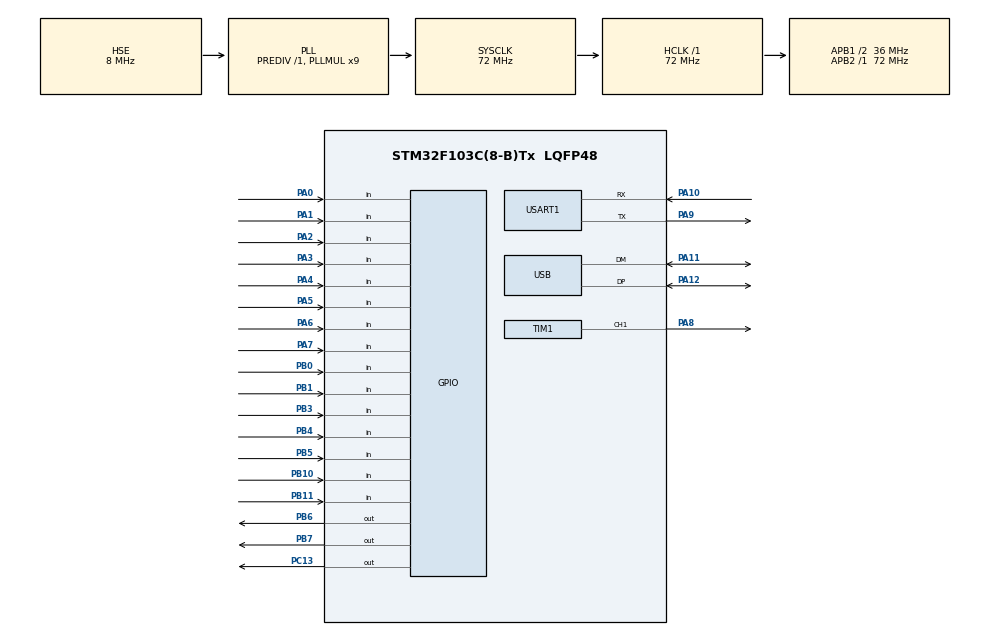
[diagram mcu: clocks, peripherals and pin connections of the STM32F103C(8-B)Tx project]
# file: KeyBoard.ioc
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Dma.Request0=TIM1_CH1
Dma.TIM1_CH1.0.Direction=DMA_MEMORY_TO_PERIPH
Dma.TIM1_CH1.0.Instance=DMA1_Channel2
Dma.TIM1_CH1.0.MemDataAlignment=DMA_MDATAALIGN_WORD
Dma.TIM1_CH1.0.MemInc=DMA_MINC_ENABLE
Dma.TIM1_CH1.0.Mode=DMA_NORMAL
Dma.TIM1_CH1.0.PeriphDataAlignment=DMA_PDATAALIGN_WORD
Dma.TIM1_CH1.0.PeriphInc=DMA_PINC_DISABLE
Dma.TIM1_CH1.0.Priority=DMA_PRIORITY_LOW
Mcu.Family=STM32F1
Mcu.Name=STM32F103C(8-B)Tx
Mcu.Package=LQFP48
NVIC.DMA1_Channel2_IRQn=true\:0\:0\:false\:false\:true\:false\:true\:true
NVIC.PriorityGroup=NVIC_PRIORITYGROUP_4
NVIC.USART1_IRQn=true\:0\:0\:false\:false\:true\:true\:true\:true
NVIC.USB_LP_CAN1_RX0_IRQn=true\:0\:0\:false\:false\:true\:false\:true\:true
PA0-WKUP.GPIO_PuPd=GPIO_PULLUP
PA0-WKUP.Signal=GPIO_Input
PA1.GPIO_PuPd=GPIO_PULLUP
PA1.Signal=GPIO_Input
PA10.Mode=Asynchronous
PA10.Signal=USART1_RX
PA11.Mode=Device
PA11.Signal=USB_DM
PA12.Mode=Device
PA12.Signal=USB_DP
PA13.Mode=Serial_Wire
PA13.Signal=SYS_JTMS-SWDIO
PA14.Mode=Serial_Wire
PA14.Signal=SYS_JTCK-SWCLK
PA2.GPIO_PuPd=GPIO_PULLUP
PA2.Signal=GPIO_Input
PA3.GPIO_PuPd=GPIO_PULLUP
PA3.Signal=GPIO_Input
PA4.GPIO_PuPd=GPIO_PULLUP
PA4.Signal=GPIO_Input
PA5.GPIO_PuPd=GPIO_PULLUP
PA5.Signal=GPIO_Input
PA6.GPIO_PuPd=GPIO_PULLUP
PA6.Signal=GPIO_Input
PA7.GPIO_PuPd=GPIO_PULLUP
PA7.Signal=GPIO_Input
PA8.Signal=S_TIM1_CH1
PA9.Mode=Asynchronous
PA9.Signal=USART1_TX
PB0.GPIO_PuPd=GPIO_PULLUP
PB0.Signal=GPIO_Input
PB1.GPIO_PuPd=GPIO_PULLUP
PB1.Signal=GPIO_Input
PB10.GPIO_PuPd=GPIO_PULLUP
PB10.Signal=GPIO_Input
PB11.GPIO_PuPd=GPIO_PULLUP
PB11.Signal=GPIO_Input
PB3.GPIO_PuPd=GPIO_PULLUP
PB3.Signal=GPIO_Input
PB4.GPIO_PuPd=GPIO_PULLUP
PB4.Signal=GPIO_Input
PB5.GPIO_PuPd=GPIO_PULLUP
PB5.Signal=GPIO_Input
PB6.GPIO_ModeDefaultOutputPP=GPIO_MODE_OUTPUT_OD
PB6.GPIO_PuPd=GPIO_PULLUP
PB6.GPIO_Speed=GPIO_SPEED_FREQ_HIGH
PB6.PinState=GPIO_PIN_SET
PB6.Signal=GPIO_Output
PB7.GPIO_ModeDefaultOutputPP=GPIO_MODE_OUTPUT_OD
PB7.GPIO_PuPd=GPIO_PULLUP
PB7.GPIO_Speed=GPIO_SPEED_FREQ_HIGH
PB7.PinState=GPIO_PIN_SET
PB7.Signal=GPIO_Output
PC13-TAMPER-RTC.GPIO_ModeDefaultOutputPP=GPIO_MODE_OUTPUT_PP
PC13-TAMPER-RTC.GPIO_PuPd=GPIO_PULLUP
PC13-TAMPER-RTC.GPIO_Speed=GPIO_SPEED_FREQ_HIGH
PC13-TAMPER-RTC.PinState=GPIO_PIN_SET
PC13-TAMPER-RTC.Signal=GPIO_Output
PC14-OSC32_IN.Mode=LSE-External-Oscillator
PC14-OSC32_IN.Signal=RCC_OSC32_IN
PC15-OSC32_OUT.Mode=LSE-External-Oscillator
PC15-OSC32_OUT.Signal=RCC_OSC32_OUT
PD0-OSC_IN.Mode=HSE-External-Oscillator
PD0-OSC_IN.Signal=RCC_OSC_IN
PD1-OSC_OUT.Mode=HSE-External-Oscillator
PD1-OSC_OUT.Signal=RCC_OSC_OUT
ProjectManager.HeapSize=0x200
ProjectManager.StackSize=0x400
ProjectManager.TargetToolchain=MDK-ARM V5.32
RCC.AHBFreq_Value=72000000
RCC.APB1CLKDivider=RCC_HCLK_DIV2
RCC.APB1Freq_Value=36000000
RCC.APB1TimFreq_Value=72000000
RCC.APB2Freq_Value=72000000
RCC.APB2TimFreq_Value=72000000
RCC.HCLKFreq_Value=72000000
RCC.PLLMUL=RCC_PLL_MUL9
RCC.SYSCLKFreq_VALUE=72000000
RCC.SYSCLKSource=RCC_SYSCLKSOURCE_PLLCLK
RCC.USBFreq_Value=48000000
RCC.USBPrescaler=RCC_USBCLKSOURCE_PLL_DIV1_5
SH.S_TIM1_CH1.0=TIM1_CH1,PWM Generation1 CH1
TIM1.Channel-PWM\ Generation1\ CH1=TIM_CHANNEL_1
TIM1.Period=89
TIM3.AutoReloadPreload=TIM_AUTORELOAD_PRELOAD_ENABLE
TIM3.Prescaler=3
USART1.VirtualMode=VM_ASYNC
USB_DEVICE.CLASS_NAME_FS=HID
USB_DEVICE.MANUFACTURER_STRING=KeyBoard
USB_DEVICE.PID_HID_FS=11451
USB_DEVICE.PRODUCT_STRING_HID_FS=KeyBoard
USB_DEVICE.VID=1145
USB_DEVICE.VirtualMode=Hid
USB_DEVICE.VirtualModeFS=Hid_FS
VP_RTC_VS_RTC_Activate.Mode=RTC_Enabled
VP_TIM1_VS_ClockSourceINT.Mode=Internal
VP_TIM3_VS_ClockSourceINT.Mode=Internal
VP_USB_DEVICE_VS_USB_DEVICE_HID_FS.Mode=HID_FS
board=custom

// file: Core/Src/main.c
/* USER CODE BEGIN Header */
/**
  ******************************************************************************
  * @file           : main.c
  * @brief          : Main program body
  ******************************************************************************
  * @attention
  *
  * Copyright (c) 2024 STMicroelectronics.
  * All rights reserved.
  *
  * This software is licensed under terms that can be found in the LICENSE file
  * in the root directory of this software component.
  * If no LICENSE file comes with this software, it is provided AS-IS.
  *
  ******************************************************************************
  */
/* USER CODE END Header */
#include "main.h"
#include "dma.h"
#include "rtc.h"
#include "tim.h"
#include "usart.h"
#include "usb_device.h"
#include "gpio.h"

/* USER CODE BEGIN Includes */
#include "KeyboardControl.h"
#include "RGB.h"
#include "CTRL.h"

/* USER CODE END Includes */

void SystemClock_Config(void);

int main(void)
{

  /* MCU Configuration--------------------------------------------------------*/

  /* Reset of all peripherals, Initializes the Flash interface and the Systick. */
  HAL_Init();

  /* Configure the system clock */
  SystemClock_Config();

  /* Initialize all configured peripherals */
  MX_GPIO_Init();
  MX_DMA_Init();
  MX_USB_DEVICE_Init();
  MX_USART1_UART_Init();
  MX_TIM1_Init();
  MX_TIM3_Init();
  MX_RTC_Init();

  /* USER CODE BEGIN 2 */
  RGB_Init();					//RGB初始化
  CTRL_Init();					//控制按键初始化

  /* USER CODE END 2 */

  /* Infinite loop */
  /* USER CODE BEGIN WHILE */
  while (1)
  {
	KeyboardCTRL();				//键盘控制
	RGB_ColorCtrl(13);			//RBG控制
	CTRL_KeyStatusRefresh();	//刷新控制按键并更新控制状态

    /* USER CODE END WHILE */

  }
}

void SystemClock_Config(void)
{
  RCC_OscInitTypeDef RCC_OscInitStruct = {0};
  RCC_ClkInitTypeDef RCC_ClkInitStruct = {0};
  RCC_PeriphCLKInitTypeDef PeriphClkInit = {0};

  /** Initializes the RCC Oscillators according to the specified parameters
  * in the RCC_OscInitTypeDef structure.
  */
  RCC_OscInitStruct.OscillatorType = RCC_OSCILLATORTYPE_LSI|RCC_OSCILLATORTYPE_HSE;
  RCC_OscInitStruct.HSEState = RCC_HSE_ON;
  RCC_OscInitStruct.HSEPredivValue = RCC_HSE_PREDIV_DIV1;
  RCC_OscInitStruct.HSIState = RCC_HSI_ON;
  RCC_OscInitStruct.LSIState = RCC_LSI_ON;
  RCC_OscInitStruct.PLL.PLLState = RCC_PLL_ON;
  RCC_OscInitStruct.PLL.PLLSource = RCC_PLLSOURCE_HSE;
  RCC_OscInitStruct.PLL.PLLMUL = RCC_PLL_MUL9;
  if (HAL_RCC_OscConfig(&RCC_OscInitStruct) != HAL_OK)
  {
    Error_Handler();
  }

  /** Initializes the CPU, AHB and APB buses clocks
  */
  RCC_ClkInitStruct.ClockType = RCC_CLOCKTYPE_HCLK|RCC_CLOCKTYPE_SYSCLK
                              |RCC_CLOCKTYPE_PCLK1|RCC_CLOCKTYPE_PCLK2;
  RCC_ClkInitStruct.SYSCLKSource = RCC_SYSCLKSOURCE_PLLCLK;
  RCC_ClkInitStruct.AHBCLKDivider = RCC_SYSCLK_DIV1;
  RCC_ClkInitStruct.APB1CLKDivider = RCC_HCLK_DIV2;
  RCC_ClkInitStruct.APB2CLKDivider = RCC_HCLK_DIV1;

  if (HAL_RCC_ClockConfig(&RCC_ClkInitStruct, FLASH_LATENCY_2) != HAL_OK)
  {
    Error_Handler();
  }
  PeriphClkInit.PeriphClockSelection = RCC_PERIPHCLK_RTC|RCC_PERIPHCLK_USB;
  PeriphClkInit.RTCClockSelection = RCC_RTCCLKSOURCE_LSI;
  PeriphClkInit.UsbClockSelection = RCC_USBCLKSOURCE_PLL_DIV1_5;
  if (HAL_RCCEx_PeriphCLKConfig(&PeriphClkInit) != HAL_OK)
  {
    Error_Handler();
  }
}

void Error_Handler(void)
{
  __disable_irq();
  while (1)
  {
  }
}
